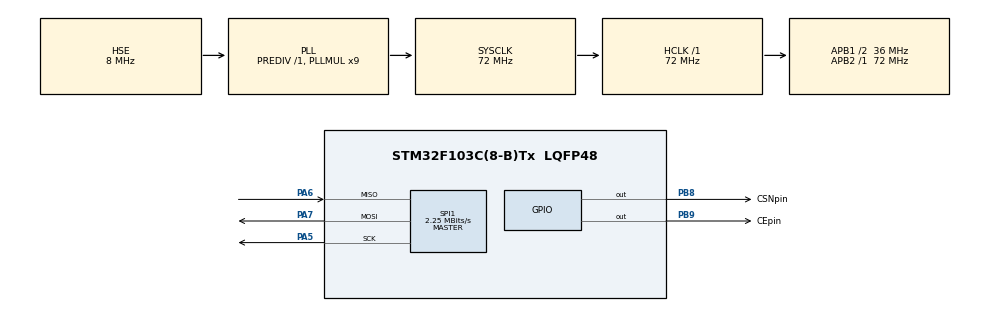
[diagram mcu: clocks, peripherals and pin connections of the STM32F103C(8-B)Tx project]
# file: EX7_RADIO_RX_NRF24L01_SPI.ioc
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Mcu.Family=STM32F1
Mcu.Name=STM32F103C(8-B)Tx
Mcu.Package=LQFP48
NVIC.PriorityGroup=NVIC_PRIORITYGROUP_4
PA13.Mode=Serial_Wire
PA13.Signal=SYS_JTMS-SWDIO
PA14.Mode=Serial_Wire
PA14.Signal=SYS_JTCK-SWCLK
PA5.Mode=Full_Duplex_Master
PA5.Signal=SPI1_SCK
PA6.Mode=Full_Duplex_Master
PA6.Signal=SPI1_MISO
PA7.Mode=Full_Duplex_Master
PA7.Signal=SPI1_MOSI
PB8.GPIO_Label=CSNpin
PB8.Signal=GPIO_Output
PB9.GPIO_Label=CEpin
PB9.Signal=GPIO_Output
PD0-OSC_IN.Mode=HSE-External-Oscillator
PD0-OSC_IN.Signal=RCC_OSC_IN
PD1-OSC_OUT.Mode=HSE-External-Oscillator
PD1-OSC_OUT.Signal=RCC_OSC_OUT
ProjectManager.HeapSize=0x200
ProjectManager.StackSize=0x400
ProjectManager.TargetToolchain=STM32CubeIDE
RCC.AHBFreq_Value=72000000
RCC.APB1CLKDivider=RCC_HCLK_DIV2
RCC.APB1Freq_Value=36000000
RCC.APB1TimFreq_Value=72000000
RCC.APB2Freq_Value=72000000
RCC.APB2TimFreq_Value=72000000
RCC.HCLKFreq_Value=72000000
RCC.PLLMUL=RCC_PLL_MUL9
RCC.PLLSourceVirtual=RCC_PLLSOURCE_HSE
RCC.SYSCLKFreq_VALUE=72000000
RCC.SYSCLKSource=RCC_SYSCLKSOURCE_PLLCLK
RCC.USBFreq_Value=72000000
SPI1.BaudRatePrescaler=SPI_BAUDRATEPRESCALER_32
SPI1.CalculateBaudRate=2.25 MBits/s
SPI1.Direction=SPI_DIRECTION_2LINES
SPI1.Mode=SPI_MODE_MASTER
SPI1.VirtualType=VM_MASTER
board=custom

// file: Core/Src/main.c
/* USER CODE BEGIN Header */
/**
  ******************************************************************************
  * @file           : main.c
  * @brief          : Main program body
  ******************************************************************************
  *						 EXEMPLO DE RADIO RECEPTOR (stm32f103c8)
  ******************************************************************************
  * Aluno:        Ruan Robert Bispo dos Santos                            2019.2
  * Orientadores: Lucas Molina e Elyson Adan Nunes Carvalho
  *
  * CODIGO DA PLACA DE INTERFACE DO MATLAB COM O STM32F103C8
  *
  * @Resumo: Código teste para a comunicação via Rádio usando o dispositivo
  * 		 transceptor NRF24L01+, e a biblioteca disponível em 3 arquivos:
  * 		 (MY_NRF24.h), (MY_NRF24.c) e (nRF24L01.h)
  * 		 Ambos alocados nas pastas: Core/Src(para .c) e Core/Inc(para .h)
  * 		 Este código exemplifica a componente de comunicação RECEPTORA de
  * 		 dados.
  *
  *			 OBS: O chip testado estava com problemas de comunicação, para
  *			      solucionar o problema foi soldado um capacitor na alimentação
  *               de ceramica com 100 nF
  *
  *
  * @Configurações:
  *   		 Clock   - 72 MHz
  *   		 SPI1	 - usado na comunicação com rádio
  *
  * Bibliotecas:
  * 		 Comunicação via rádio do receptor - biblioteca "MY_NRF24.h"
  *
  *
  ******************************************************************************
  * @attention
  *
  * <h2><center>&copy; Copyright (c) 2020 STMicroelectronics.
  * All rights reserved.</center></h2>
  *
  * This software component is licensed by ST under BSD 3-Clause license,
  * the "License"; You may not use this file except in compliance with the
  * License. You may obtain a copy of the License at:
  *                        opensource.org/licenses/BSD-3-Clause
  *
  ******************************************************************************
  */
/* USER CODE END Header */

#include "main.h"

/* USER CODE BEGIN Includes */
#include "MY_NRF24.h"
/* USER CODE END Includes */

SPI_HandleTypeDef hspi1;

/* USER CODE BEGIN PV */
///////////////////// VARIAVEIS //////////////////////////////

uint64_t RxpipeAddrs = 0x11223344AA; // endereço do radio
char myRxData[32];					 // buffer receptor radio
char myAckPayload[32] = "Ack ok";    // palavra usada para reconhecimento

///////////////////////////////////////////////////////////////
/* USER CODE END PV */

void SystemClock_Config(void);
static void MX_GPIO_Init(void);
static void MX_SPI1_Init(void);

int main(void)
{

  /* MCU Configuration--------------------------------------------------------*/

  /* Reset of all peripherals, Initializes the Flash interface and the Systick. */
  HAL_Init();

  /* Configure the system clock */
  SystemClock_Config();

  /* Initialize all configured peripherals */
  MX_GPIO_Init();
  MX_SPI1_Init();
  /* USER CODE BEGIN 2 */

	/////////////////////**** RECEPTOR ****///////////////////////////

	NRF24_begin(CEpin_GPIO_Port,CSNpin_Pin,CEpin_Pin,hspi1);
	printRadioSettings();
	NRF24_setAutoAck(false); //Ativar para o caso de reconhecimento
	NRF24_setChannel(52);    //Deve ser o mesmo do transmissor
	NRF24_setPayloadSize(32);
	NRF24_openReadingPipe(1, RxpipeAddrs);
	//NRF24_enableDynamicPayloads(); //Descomentar para reconhecimento
	//NRF24_enableAckPayload();      //Descomentar para reconhecimento
	NRF24_startListening();

	//////////////////////////////////////////////////////////////////
	//OBS: O rádio pode ser configurado no modo simples e no modo que
	//possui uma palavra de reconhecimento (Ack), ou seja, assim que o
	//receptor captar o pacote enviado pelo transmissor ele envia um
	//sinal de "ok" assim é possível ter um conhecimento mais preciso
	//se houve perda de pacotes no caminho.

  /* USER CODE END 2 */

  /* Infinite loop */
  /* USER CODE BEGIN WHILE */
  while (1)
  {
	  /////////////////////////////////////////////////////////////////
	  /////////////////////////// RADIO ///////////////////////////////
	  /////////////////////////////////////////////////////////////////
	  if(NRF24_available()) //verifica se há dados disponíveis
		{
			NRF24_read(myRxData, 32); // Lê dados recebido
			//NRF24_writeAckPayload(1, myAckPayload, 32);//Transmite de volta (descomentar no caso de reconhecimento)
		}

	  /////////////////////////////////////////////////////////////////

    /* USER CODE END WHILE */

  }
}

void SystemClock_Config(void)
{
  RCC_OscInitTypeDef RCC_OscInitStruct = {0};
  RCC_ClkInitTypeDef RCC_ClkInitStruct = {0};

  /** Initializes the CPU, AHB and APB busses clocks
  */
  RCC_OscInitStruct.OscillatorType = RCC_OSCILLATORTYPE_HSE;
  RCC_OscInitStruct.HSEState = RCC_HSE_ON;
  RCC_OscInitStruct.HSEPredivValue = RCC_HSE_PREDIV_DIV1;
  RCC_OscInitStruct.HSIState = RCC_HSI_ON;
  RCC_OscInitStruct.PLL.PLLState = RCC_PLL_ON;
  RCC_OscInitStruct.PLL.PLLSource = RCC_PLLSOURCE_HSE;
  RCC_OscInitStruct.PLL.PLLMUL = RCC_PLL_MUL9;
  if (HAL_RCC_OscConfig(&RCC_OscInitStruct) != HAL_OK)
  {
    Error_Handler();
  }
  /** Initializes the CPU, AHB and APB busses clocks
  */
  RCC_ClkInitStruct.ClockType = RCC_CLOCKTYPE_HCLK|RCC_CLOCKTYPE_SYSCLK
                              |RCC_CLOCKTYPE_PCLK1|RCC_CLOCKTYPE_PCLK2;
  RCC_ClkInitStruct.SYSCLKSource = RCC_SYSCLKSOURCE_PLLCLK;
  RCC_ClkInitStruct.AHBCLKDivider = RCC_SYSCLK_DIV1;
  RCC_ClkInitStruct.APB1CLKDivider = RCC_HCLK_DIV2;
  RCC_ClkInitStruct.APB2CLKDivider = RCC_HCLK_DIV1;

  if (HAL_RCC_ClockConfig(&RCC_ClkInitStruct, FLASH_LATENCY_2) != HAL_OK)
  {
    Error_Handler();
  }
}

static void MX_SPI1_Init(void)
{

  /* SPI1 parameter configuration*/
  hspi1.Instance = SPI1;
  hspi1.Init.Mode = SPI_MODE_MASTER;
  hspi1.Init.Direction = SPI_DIRECTION_2LINES;
  hspi1.Init.DataSize = SPI_DATASIZE_8BIT;
  hspi1.Init.CLKPolarity = SPI_POLARITY_LOW;
  hspi1.Init.CLKPhase = SPI_PHASE_1EDGE;
  hspi1.Init.NSS = SPI_NSS_SOFT;
  hspi1.Init.BaudRatePrescaler = SPI_BAUDRATEPRESCALER_32;
  hspi1.Init.FirstBit = SPI_FIRSTBIT_MSB;
  hspi1.Init.TIMode = SPI_TIMODE_DISABLE;
  hspi1.Init.CRCCalculation = SPI_CRCCALCULATION_DISABLE;
  hspi1.Init.CRCPolynomial = 10;
  if (HAL_SPI_Init(&hspi1) != HAL_OK)
  {
    Error_Handler();
  }

}

static void MX_GPIO_Init(void)
{
  GPIO_InitTypeDef GPIO_InitStruct = {0};

  /* GPIO Ports Clock Enable */
  __HAL_RCC_GPIOD_CLK_ENABLE();
  __HAL_RCC_GPIOA_CLK_ENABLE();
  __HAL_RCC_GPIOB_CLK_ENABLE();

  /*Configure GPIO pin Output Level */
  HAL_GPIO_WritePin(GPIOB, CSNpin_Pin|CEpin_Pin, GPIO_PIN_RESET);

  /*Configure GPIO pins : CSNpin_Pin CEpin_Pin */
  GPIO_InitStruct.Pin = CSNpin_Pin|CEpin_Pin;
  GPIO_InitStruct.Mode = GPIO_MODE_OUTPUT_PP;
  GPIO_InitStruct.Pull = GPIO_NOPULL;
  GPIO_InitStruct.Speed = GPIO_SPEED_FREQ_LOW;
  HAL_GPIO_Init(GPIOB, &GPIO_InitStruct);

}

void Error_Handler(void)
{
}

/************************ (C) COPYRIGHT STMicroelectronics *****END OF FILE****/
